# FUSB15200 register map
Vendor: ON Semiconductor; Series: FUSB15200; File version: 1.0
CPU: CM0+ r1p0, little endian, no MPU, no FPU, 3 interrupt priority bits
Registers are 32-bit, read-write, reset 0x0 unless marked. A register's access mark holds for its fields unless they carry their own. Offsets are from the block's base; [hi:lo] are bit positions; {n}, {i} and the like mark numbered series.

## Timer_0
Base 0x40200000
0x00 GPT0_TIMER1LOAD (reset mask 0x1)
  [31:0] timer1_load
0x04 GPT0_TIMER1VALUE reset 0xFFFFFFFF (reset mask 0x1)
  [31:0] timer1_value ro
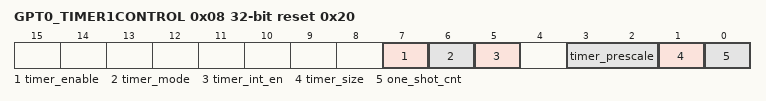
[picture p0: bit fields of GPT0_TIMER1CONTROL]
0x08 GPT0_TIMER1CONTROL reset 0x20 (reset mask 0xE7)
  [7] timer_enable, [6] timer_mode, [5] timer_int_en, [3:2] timer_prescale, [1] timer_size, [0] one_shot_cnt
0x0C GPT0_TIMER1INTCLR (reset mask 0x1)
  [31:0] timewr1_int_clr wo
0x10 GPT0_TIMER1RIS
  [0] timer1_int_raw ro
0x14 GPT0_TIMER1MIS
  [0] timer1_int ro
0x18 GPT0_TIMER1BGLOAD (reset mask 0x1)
  [31:0] timer1_bgload

## Timer_1
Base 0x40300000
0x00 GPT1_TIMER1LOAD (reset mask 0x1)
  [31:0] timer1_load
0x04 GPT1_TIMER1VALUE reset 0xFFFFFFFF (reset mask 0x1)
  [31:0] timer1_value ro
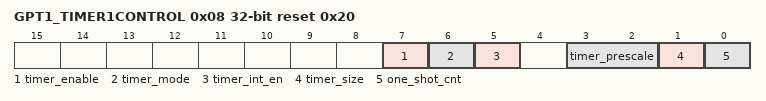
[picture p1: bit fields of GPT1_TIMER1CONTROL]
0x08 GPT1_TIMER1CONTROL reset 0x20 (reset mask 0xE7)
  [7] timer_enable, [6] timer_mode, [5] timer_int_en, [3:2] timer_prescale, [1] timer_size, [0] one_shot_cnt
0x0C GPT1_TIMER1INTCLR (reset mask 0x1)
  [31:0] timewr1_int_clr wo
0x10 GPT1_TIMER1RIS
  [0] timer1_int_raw ro
0x14 GPT1_TIMER1MIS
  [0] timer1_int ro
0x18 GPT1_TIMER1BGLOAD (reset mask 0x1)
  [31:0] timer1_bgload

## Wake_Up_Timer
Base 0x40400000
0x00 WUT_TIMER1LOAD (reset mask 0x1)
  [31:0] timer1_load
0x04 WUT_TIMER1VALUE reset 0xFFFFFFFF (reset mask 0x1)
  [31:0] timer1_value ro
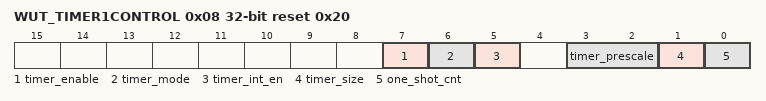
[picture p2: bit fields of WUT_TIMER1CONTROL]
0x08 WUT_TIMER1CONTROL reset 0x20 (reset mask 0xE7)
  [7] timer_enable, [6] timer_mode, [5] timer_int_en, [3:2] timer_prescale, [1] timer_size, [0] one_shot_cnt
0x0C WUT_TIMER1INTCLR (reset mask 0x1)
  [31:0] timewr1_int_clr wo
0x10 WUT_TIMER1RIS
  [0] timer1_int_raw ro
0x14 WUT_TIMER1MIS
  [0] timer1_int ro
0x18 WUT_TIMER1BGLOAD (reset mask 0x1)
  [31:0] timer1_bgload

## NTC_Port_A_B_Interface
Base 0x40500000
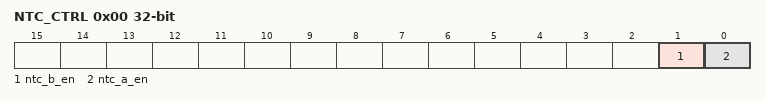
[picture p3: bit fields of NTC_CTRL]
0x00 NTC_CTRL
  [1] ntc_b_en, [0] ntc_a_en

## PORT_Interface
Base 0x40700000
0x00 ANA_EN (reset mask 0x1)
  [19:0] PORT_ANEN
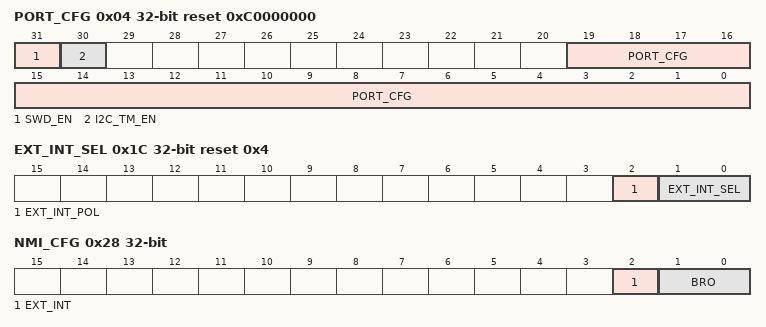
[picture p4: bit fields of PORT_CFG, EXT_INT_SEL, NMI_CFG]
0x04 PORT_CFG reset 0xC0000000 (reset mask 0xC0000001)
  [31] SWD_EN, [30] I2C_TM_EN, [19:0] PORT_CFG
0x08 PULL_UP (reset mask 0x1)
  [19:0] PORT_PU
0x0C PULL_DOWN (reset mask 0x1)
  [19:0] PORT_PD
0x1C EXT_INT_SEL reset 0x4 (reset mask 0x5)
  [2] EXT_INT_POL, [1:0] EXT_INT_SEL
0x20 EXT_INT_EN
  [0] EXT_INT_EN
0x24 EXT_INT_STS
  [0] EXT_INT_STS wo
0x28 NMI_CFG (reset mask 0x5)
  [2] EXT_INT, [1:0] BRO

## GPIO_Interface
Base 0x40800000
0x00 GPIO_DIR (reset mask 0x1)
  [19:0] GPIO_DIR
0x04 GPIO_OD (reset mask 0x1)
  [19:0] GPIO_OD
0x08 GPIO_OUT (reset mask 0x1)
  [19:0] GPIO_OUT
0x0C GPIO_IN (reset mask 0x1)
  [19:0] GPIO_IN ro
0x10 GPIO_INT_EN (reset mask 0x1)
  [19:0] GPIO_INT_EN
0x14 GPIO_INT_POL (reset mask 0x1)
  [19:0] GPIO_INT_POL
0x18 GPIO_INT_TYP (reset mask 0x1)
  [19:0] GPIO_INT_TYP
0x1C GPIO_INT_STS (reset mask 0x1)
  [19:0] GPIO_INT_STS wo
0x20 GPIO_IN_EN reset 0x12 (reset mask 0x1)
  [19:0] GPIO_IN_EN

## ADC_Interface
Base 0x40900000
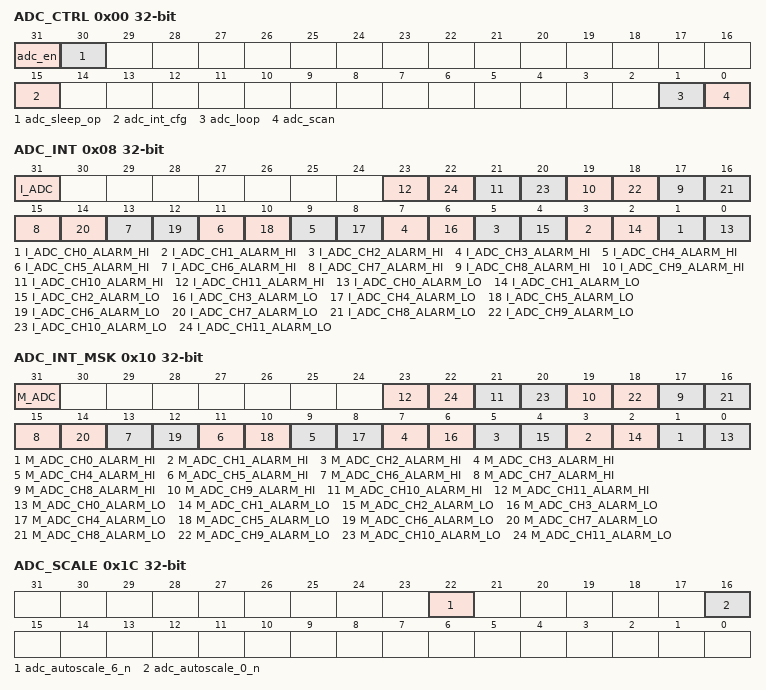
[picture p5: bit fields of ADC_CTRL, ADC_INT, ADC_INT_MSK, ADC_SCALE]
0x00 ADC_CTRL
  [31] adc_en, [30] adc_sleep_op, [15] adc_int_cfg, [1] adc_loop, [0] adc_scan
0x04 ADC_STS (reset mask 0x1)
  [11:0] adc_done_n ro
0x08 ADC_INT
  [31] I_ADC wo, [2n+1] I_ADC_CH{n}_ALARM_HI wo (n=0..11), [2n] I_ADC_CH{n}_ALARM_LO wo (n=0..11)
0x10 ADC_INT_MSK
  [31] M_ADC, [2n+1] M_ADC_CH{n}_ALARM_HI (n=0..11), [2n] M_ADC_CH{n}_ALARM_LO (n=0..11)
0x18 ADC_CH_EN (reset mask 0x1)
  [11:0] ADC_CH_EN
0x1C ADC_SCALE
  [22] adc_autoscale_6_n, [16] adc_autoscale_0_n
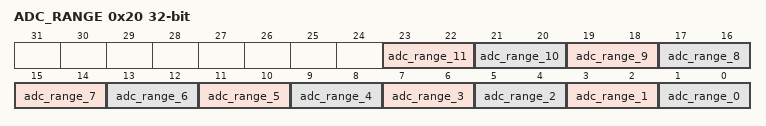
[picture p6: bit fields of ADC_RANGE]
0x20 ADC_RANGE (reset mask 0x555555)
  [2n+1:2n] adc_range_{n} ro (n=7..11), [13:12] adc_range_6, [2n+1:2n] adc_range_{n} ro (n=1..5), [1:0] adc_range_0
0x24 ADC_AVG
  [0] adc_avg
{0x28+4i} ADC_DATA{i} (reset mask 0x1) (i=0..11)
  [11:0] ADC_DATA{i} ro
{0x68+8i} ADC_CH{i}_ALARM_LO (reset mask 0x1) (i=0..11)
  [11:0] ADC_CH{i}_ALARM_LO
{0x6C+8i} ADC_CH{i}_ALARM_HI (reset mask 0x1) (i=0..11)
  [11:0] ADC_CH{i}_ALARM_HI
